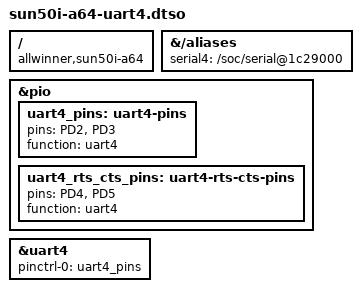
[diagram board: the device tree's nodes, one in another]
/dts-v1/;
/plugin/;

/ {
	compatible = "allwinner,sun50i-a64";

	fragment@0 {
		target-path = "/aliases";
		__overlay__ {
			serial4 = "/soc/serial@1c29000";
		};
	};

	fragment@1 {
		target = <&pio>;
		__overlay__ {
			uart4_pins: uart4-pins {
				pins = "PD2", "PD3";
				function = "uart4";
			};

			uart4_rts_cts_pins: uart4-rts-cts-pins {
				pins = "PD4", "PD5";
				function = "uart4";
			};
		};
	};

	fragment@2 {
		target = <&uart4>;
		 __overlay__ {
			pinctrl-names = "default";
			pinctrl-0 = <&uart4_pins>;
			status = "okay";
		};
	};
};
